# ATtiny261A device description
Architecture: AVR8; Family: tinyAVR
Registers are 8-bit, access not given, no defined reset value unless marked. A register's access mark holds for its fields unless they carry their own. Offsets are from the block's base; [hi:lo] are bit positions.

## AC — Analog Comparator
Instances: AC 0x00
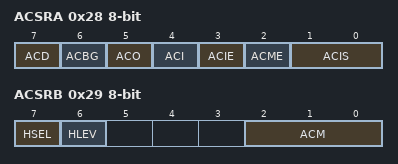
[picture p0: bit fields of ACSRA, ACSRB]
0x28 ACSRA — Analog Comparator Control And Status Register A
  [7] ACD — Analog Comparator Disable
  [6] ACBG — Analog Comparator Bandgap Select
  [5] ACO — Analog Compare Output
  [4] ACI — Analog Comparator Interrupt Flag
  [3] ACIE — Analog Comparator Interrupt Enable
  [2] ACME — Analog Comparator Multiplexer Enable
  [1:0] ACIS — Analog Comparator Interrupt Mode Select bits
    0=Interrupt on Toggle; 2=Interrupt on Falling Edge; 3=Interrupt on Rising Edge
0x29 ACSRB — Analog Comparator Control And Status Register B
  [7] HSEL — Hysteresis Select
  [6] HLEV — Hysteresis Level
  [2:0] ACM — Analog Comparator Multiplexer

## USI — Universal Serial Interface
Instances: USI 0x00
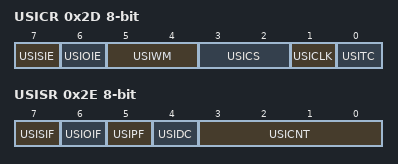
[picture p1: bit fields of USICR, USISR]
0x2D USICR — USI Control Register
  [7] USISIE — Start Condition Interrupt Enable
  [6] USIOIE — Counter Overflow Interrupt Enable
  [5:4] USIWM — USI Wire Mode Bits
    0=Normal Operation; 1=Three-Wire Mode; 2=Two-Wire Mode; 3=Two-Wire Mode Held Low
  [3:2] USICS — USI Clock Source Select Bits
  [1] USICLK — Clock Strobe
  [0] USITC — Toggle Clock Port Pin
0x2E USISR — USI Status Register
  [7] USISIF — Start Condition Interrupt Flag
  [6] USIOIF — Counter Overflow Interrupt Flag
  [5] USIPF — Stop Condition Flag
  [4] USIDC — Data Output Collision
  [3:0] USICNT — USI Counter Value Bits
0x2F USIDR — USI Data Register
0x30 USIBR — USI Buffer Register
0x31 USIPP bits used 0 — USI Pin Position

## EEPROM
Instances: EEPROM 0x00
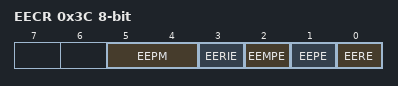
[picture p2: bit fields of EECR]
0x3C EECR — EEPROM Control Register
  [5:4] EEPM — EEPROM Programming Mode Bits
    0=Erase and Write in one operation; 1=Erase Only; 2=Write Only
  [3] EERIE — EEPROM Ready Interrupt Enable
  [2] EEMPE — EEPROM Master Write Enable
  [1] EEPE — EEPROM Write Enable
  [0] EERE — EEPROM Read Enable
0x3D EEDR — EEPROM Data Register
0x3E EEAR 16-bit bits used 8:0 — EEPROM Address Register Bytes

## WDT — Watchdog Timer
Instances: WDT 0x00
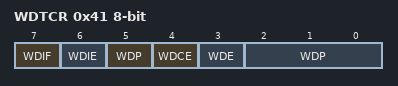
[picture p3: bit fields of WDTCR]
0x41 WDTCR — Watchdog Timer Control Register
  [7] WDIF — Watchdog Timeout Interrupt Flag
  [6] WDIE — Watchdog Timeout Interrupt Enable
  [4] WDCE — Watchdog Change Enable
  [3] WDE — Watch Dog Enable
  [5,2:0] WDP — Watchdog Timer Prescaler Bits
    0=Oscillator Cycles 2K; 1=Oscillator Cycles 4K; 2=Oscillator Cycles 8K; 3=Oscillator Cycles 16K; 4=Oscillator Cycles 32K; 5=Oscillator Cycles 64K; 6=Oscillator Cycles 128K; 7=Oscillator Cycles 256K; 8=Oscillator Cycles 512K; 9=Oscillator Cycles 1024K

## TC0 (TC8 module) — Timer/Counter, 8-bit
Instances: TC0 0x00
0x32 OCR0B — Timer/Counter0 Output Compare Register
0x33 OCR0A — Timer/Counter0 Output Compare Register
0x34 TCNT0H — Timer/Counter0 High
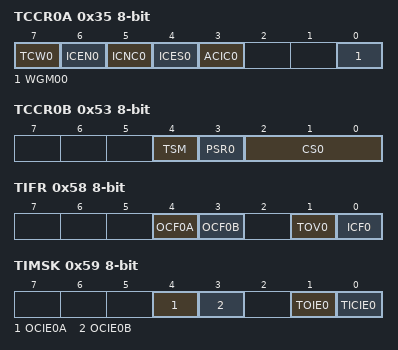
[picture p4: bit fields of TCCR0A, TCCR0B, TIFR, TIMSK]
0x35 TCCR0A — Timer/Counter Control Register A
  [7] TCW0 — Timer/Counter 0 Width
  [6] ICEN0 — Input Capture Mode Enable
  [5] ICNC0 — Input Capture Noice Canceler
  [4] ICES0 — Input Capture Edge Select
  [3] ACIC0 — Analog Comparator Input Capture Enable
  [0] WGM00 — Waveform Generation Mode
0x52 TCNT0L — Timer/Counter0 Low
0x53 TCCR0B — Timer/Counter Control Register B
  [4] TSM — Timer/Counter Synchronization Mode
  [3] PSR0 — Timer/Counter 0 Prescaler Reset
  [2:0] CS0 — Clock Select
    0=No Clock Source (Stopped); 1=Running, No Prescaling; 2=Running, CLK/8; 3=Running, CLK/64; 4=Running, CLK/256; 5=Running, CLK/1024; 6=Running, ExtClk Tx Falling Edge; 7=Running, ExtClk Tx Rising Edge
0x58 TIFR — Timer/Counter0 Interrupt Flag register
  [4] OCF0A — Timer/Counter0 Output Compare Flag 0A
  [3] OCF0B — Timer/Counter0 Output Compare Flag 0B
  [1] TOV0 — Timer/Counter0 Overflow Flag
  [0] ICF0 — Timer/Counter0 Input Capture Flag
0x59 TIMSK — Timer/Counter Interrupt Mask Register
  [4] OCIE0A — Timer/Counter0 Output Compare Match A Interrupt Enable
  [3] OCIE0B — Timer/Counter0 Output Compare Match B Interrupt Enable
  [1] TOIE0 — Timer/Counter0 Overflow Interrupt Enable
  [0] TICIE0 — Timer/Counter0 Input Capture Interrupt Enable
